# psoc6_03 register map
Vendor: Cypress Semiconductor; Series: PSoC6_03; File version: 1.0
CPU: CM4 r0p1, little endian, MPU, FPU, VTOR, 3 interrupt priority bits
Registers are 32-bit, read-write, reset 0x0 unless marked. A register's access mark holds for its fields unless they carry their own. Offsets are from the block's base; [hi:lo] are bit positions; {n}, {i} and the like mark numbered series; 'fields as' and 'values as' point back to an identical list; <NAME> marks a mode.

## CPUSS — CPU subsystem (CPUSS)
Base 0x40200000
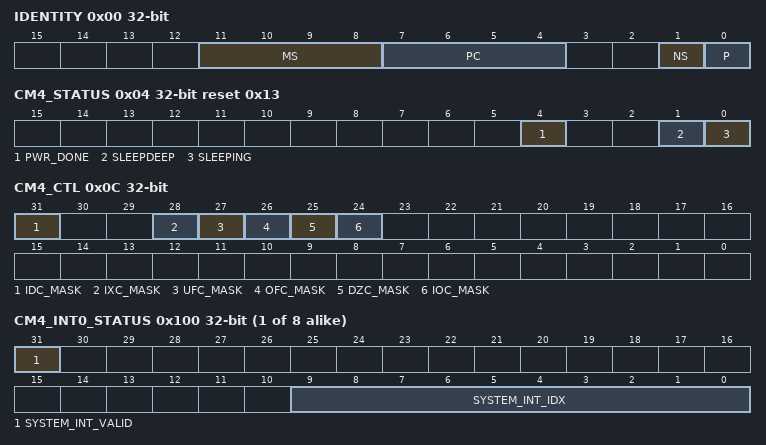
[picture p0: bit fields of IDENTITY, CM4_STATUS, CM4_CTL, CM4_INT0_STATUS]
0x00 IDENTITY ro reset not defined
  [11:8] MS — This field specifies the bus master identifier of the transfer that reads the register.
  [7:4] PC — This field specifies the protection context of the transfer that reads the register.
  [1] NS — This field specifies the security setting ('0': secure mode; '1': non-secure mode) of the transfer that reads the register.
  [0] P — This field specifies the privileged setting ('0': user mode; '1': privileged mode) of the transfer that reads the register.
0x04 CM4_STATUS ro reset 0x13
  [4] PWR_DONE — After a PWR_MODE change this flag indicates if the new power mode has taken effect or not. Note: this flag can also change as a result of a change in debug power up req
  [1] SLEEPDEEP — Specifies if the CPU is in Sleep or DeepSleep power mode. See SLEEPING field.
  [0] SLEEPING — Specifies if the CPU is in Active, Sleep or DeepSleep power mode: - Active power mode: SLEEPING is '0'. - Sleep power mode: SLEEPING is '1' and SLEEPDEEP is '0'. - DeepSleep power mode: SLEEPING is '1' and SLEEPDEEP is '1'.
0x08 CM4_CLOCK_CTL — CM4 clock control
  [15:8] FAST_INT_DIV — Specifies the fast clock divider (from the high frequency clock 'clk_hf' to the peripheral clock 'clk_fast'). Integer division by (1+FAST_INT_DIV). Allows for integer divisions in the range [1, 256] (FAST_INT_DIV is in the range [0, 255]). Note that this field is retained. However, the counter that is used to implement the division is not and will be initialized by HW to '0' when transitioning from DeepSleep to Active power mode.
0x0C CM4_CTL — CM4 control
  [31] IDC_MASK — CPU FPU exception mask for the CPU's FPCSR.IDC 'input denormalized' exception condition: '0': The CPU's exception condition does NOT activate the CPU's floating point interrupt. '1': the CPU's exception condition activates the CPU's floating point interrupt. Note: if the CPU FPCSR.FZ field is set to '1', denormalized inputs are 'flushed to zero'. Dependent on the FPU algorithm, this may or may not occur frequently. To prevent frequent CPU FPU interrupts as a result of denormalized inputs, this field may be set to '0'.
  [28] IXC_MASK — CPU FPU exception mask for the CPU's FPCSR.IXC 'inexact' exception condition: '0': The CPU's exception condition does NOT activate the CPU's floating point interrupt. '1': the CPU's exception condition activates the CPU's floating point interrupt. Note: the 'inexact' condition is set as a result of rounding. Rounding may occur frequently and is typically not an error condition. To prevent frequent CPU FPU interrupts as a result of rounding, this field is typically set to '0'.
  [27] UFC_MASK — CPU FPU exception mask for the CPU's FPCSR.UFC 'underflow' exception condition: '0': The CPU's exception condition does NOT activate the CPU's floating point interrupt. '1': the CPU's exception condition activates the CPU's floating point interrupt.
  [26] OFC_MASK — CPU FPU exception mask for the CPU's FPCSR.OFC 'overflow' exception condition: '0': The CPU's exception condition does NOT activate the CPU's floating point interrupt. '1': the CPU's exception condition activates the CPU's floating point interrupt.
  [25] DZC_MASK — CPU FPU exception mask for the CPU's FPCSR.DZC 'divide by zero' exception condition: '0': The CPU's exception condition does NOT activate the CPU's floating point interrupt. '1': the CPU's exception condition activates the CPU's floating point interrupt.
  [24] IOC_MASK — CPU floating point unit (FPU) exception mask for the CPU's FPCSR.IOC 'invalid operation' exception condition: '0': The CPU's exception condition does NOT activate the CPU's floating point interrupt. '1': the CPU's exception condition activates the CPU's floating point interrupt. Note: the ARM architecture does NOT support FPU exceptions; i.e. there is no precise FPU exception handler. Instead, FPU conditions are captured in the CPU's FPCSR register and the conditions are provided as CPU interface signals. The interface signals are 'masked' with the fields a provide by this register (CM7_0_CTL). The 'masked' signals are reduced/OR-ed into a single CPU floating point interrupt signal. The associated CPU interrupt handler allows for imprecise handling of FPU exception conditions. Note: the CPU's FPCSR exception conditions are 'sticky'. Typically, the CPU FPU interrupt handler will clear the exception condition(s) to '0'. Note: by default, the FPU exception masks are '0'. Therefore, FPU exception conditions will NOT activate the CPU's floating point interrupt.
{0x100+4i} CM4_INT{i}_STATUS ro (reset mask 0x80000000) (i=0..7) — CM4 interrupt {i} status
  [31] SYSTEM_INT_VALID — See description of CM0_INT0_STATUS.
  [9:0] SYSTEM_INT_IDX — Lowest CM4 activated system interrupt index for CPU interrupt {i}. See description of CM0_INT0_STATUS.
0x200 CM4_VECTOR_TABLE_BASE
  [31:10] ADDR22 — Address of CM4 vector table. This register is used for CM4 warm and cold boot purposes: the CM0+ CPU initializes the CM4_VECTOR_TABLE_BASE register and the CM4 boot code uses the register to initialize the CM4 internal VTOR register. Note: the CM4 vector table is at an address that is a 1024 B multiple.
{0x240+4i} CM4_NMI_CTL[{i}] (i=0..3) reset 0x3FF — CM4 NMI control
  [9:0] SYSTEM_INT_IDX — System interrupt select for CPU NMI. The reset value ('1023') ensures that the CPU NMI is NOT connected to any system interrupt after DeepSleep reset.
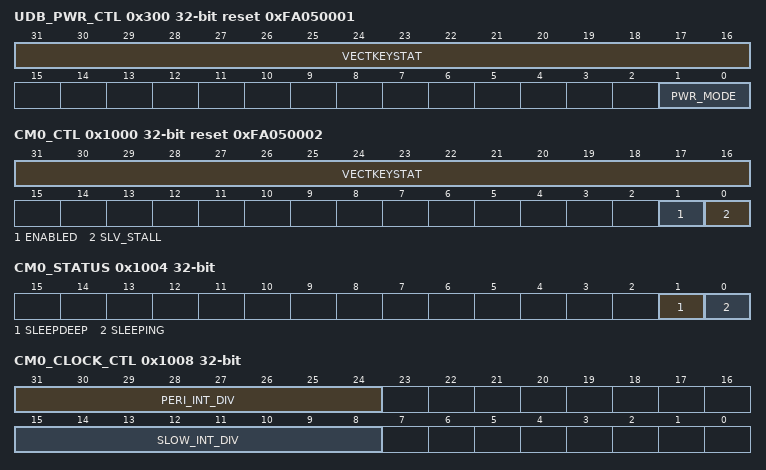
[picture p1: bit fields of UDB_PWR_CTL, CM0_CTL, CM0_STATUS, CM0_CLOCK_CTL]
0x300 UDB_PWR_CTL reset 0xFA050001 — UDB power control
  [31:16] VECTKEYSTAT ro — Register key (to prevent accidental writes). - Should be written with a 0x05fa key value for the write to take effect. - Always reads as 0xfa05.
  [1:0] PWR_MODE — Set Power mode for UDBs
    0=OFF (See CM4_PWR_CTL); 1=RESET (See CM4_PWR_CTL); 2=RETAINED (See CM4_PWR_CTL); 3=ENABLED (See CM4_PWR_CTL)
0x304 UDB_PWR_DELAY_CTL reset 0x12C — UDB power control
  [9:0] UP — Number clock cycles delay needed after power domain power up
0x1000 CM0_CTL reset 0xFA050002 — CM0+ control
  [31:16] VECTKEYSTAT ro — Register key (to prevent accidental writes). - Should be written with a 0x05fa key value for the write to take effect. - Always reads as 0xfa05. Note: Although the SW attribute for this field says ''R', SW need to write the key 0x05fa in this field for this register write to happen. This is a built in protection provided to prevent accidental writes from SW.
  [1] ENABLED — Processor enable: '0': Disabled. Processor clock is turned off and reset is activated. After SW clears this field to '0', HW automatically sets this field to '1'. This effectively results in a CM0+ reset, followed by a CM0+ warm boot. '1': Enabled. Note: The intent is that this bit is modified only through an external probe or by the CM4 while the CM0+ is in Sleep or DeepSleep power mode. If this field is cleared to '0' by the CM0+ itself, it should be done under controlled conditions (such that undesirable side effects can be prevented). Note: The CM0+ CPU has a AIRCR.SYSRESETREQ register field that allows the CM0+ to reset the complete device (ENABLED only disables/enables the CM0+), resulting in a warm boot. This CPU register field has similar 'built-in protection' as this CM0_CTL register to prevent accidental system writes (the upper 16-bits of the register need to be written with a 0x05fa key value; see CPU user manual for more details).
  [0] SLV_STALL — Processor debug access control: '0': Access. '1': Stall access. This field is used to stall/delay debug accesses. This is useful to protect execution of code that needs to be protected from debug accesses.
0x1004 CM0_STATUS ro
  [1] SLEEPDEEP — Specifies if the CPU is in Sleep or DeepSleep power mode. See SLEEPING field.
  [0] SLEEPING — Specifies if the CPU is in Active, Sleep or DeepSleep power mode: - Active power mode: SLEEPING is '0'. - Sleep power mode: SLEEPING is '1' and SLEEPDEEP is '0'. - DeepSleep power mode: SLEEPING is '1' and SLEEPDEEP is '1'.
0x1008 CM0_CLOCK_CTL — CM0+ clock control
  [31:24] PERI_INT_DIV — Specifies the peripheral clock divider (from the high frequency clock 'clk_hf' to the peripheral clock 'clk_peri'). Integer division by (1+PERI_INT_DIV). Allows for integer divisions in the range [1, 256] (PERI_INT_DIV is in the range [0, 255]). Note that this field is retained. However, the counter that is used to implement the division is not and will be initialized by HW to '0' when transitioning from DeepSleep to Active power mode. Note that Fperi <= Fperi_max. Fperi_max is likely to be smaller than Fhf_max. In other words, if Fhf = Fhf_max, PERI_INT_DIV should not be set to '0'.
  [15:8] SLOW_INT_DIV — Specifies the slow clock divider (from the peripheral clock 'clk_peri' to the slow clock 'clk_slow'). Integer division by (1+SLOW_INT_DIV). Allows for integer divisions in the range [1, 256] (SLOW_INT_DIV is in the range [0, 255]). Note that this field is retained. However, the counter that is used to implement the division is not and will be initialized by HW to '0' when transitioning from DeepSleep to Active power mode.
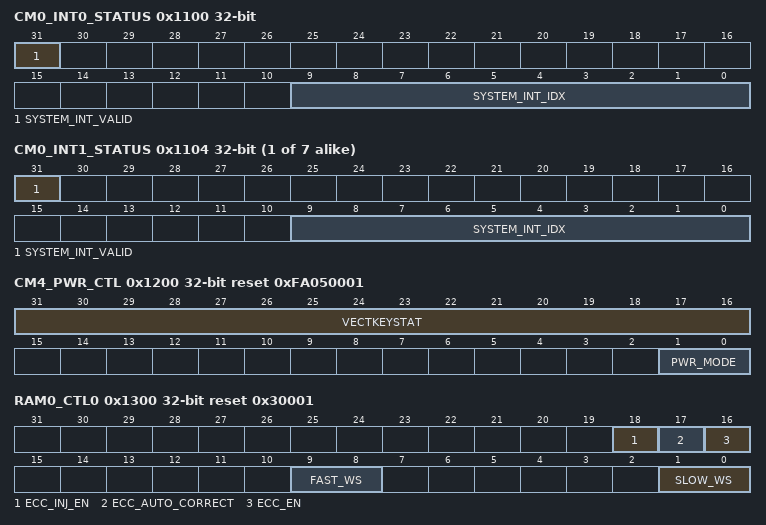
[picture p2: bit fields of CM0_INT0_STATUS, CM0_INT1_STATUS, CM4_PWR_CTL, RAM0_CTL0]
0x1100 CM0_INT0_STATUS ro (reset mask 0x80000000) — CM0+ interrupt 0 status
  [31] SYSTEM_INT_VALID — Valid indication for SYSTEM_INT_IDX. When '0', no system interrupt for CPU interrupt 0 is valid/activated.
  [9:0] SYSTEM_INT_IDX — Lowest CM0+ activated system interrupt index for CPU interrupt 0. Multiple system interrupts can be mapped on the same CPU interrupt. The selected system interrupt is the system interrupt with the lowest system interrupt index that has an activated interrupt request at the time of the fetch (system_interrupts[SYSTEM_INT_IDX] is '1'). The CPU interrupt handler SW can read SYSTEM_INT_IDX to determine the system interrupt that activated the handler.
{0x1100+4i} CM0_INT{i}_STATUS ro (reset mask 0x80000000) (i=1..7) — CM0+ interrupt {i} status
  [31] SYSTEM_INT_VALID — See description of CM0_INT0_STATUS.
  [9:0] SYSTEM_INT_IDX — Lowest CM0+ activated system interrupt index for CPU interrupt {i}. See description of CM0_INT0_STATUS.
0x1120 CM0_VECTOR_TABLE_BASE
  [31:8] ADDR24 — Address of CM0+ vector table. This register is used for CM0+ warm boot purposes: the CM0+ warm boot code uses the register to initialize the CM0+ internal VTOR register. Note: the CM0+ vector table is at an address that is a 256 B multiple.
{0x1140+4i} CM0_NMI_CTL[{i}] (i=0..3) reset 0x3FF — CM0+ NMI control
  fields as CM4_NMI_CTL[0]
0x1200 CM4_PWR_CTL reset 0xFA050001 — CM4 power control
  [31:16] VECTKEYSTAT ro — Register key (to prevent accidental writes). - Should be written with a 0x05fa key value for the write to take effect. - Always reads as 0xfa05. Note: Although the SW attribute for this field says ''R', SW need to write the key 0x05fa in this field for this register write to happen. This is a built in protection provided to prevent accidental writes from SW.
  [1:0] PWR_MODE — Power mode.
    0=OFF (Switch CM4 off Power off, clock off, isolate, reset and no retain.); 1=RESET (Reset CM4 Clock off, no isolated, no retain and reset. Note: The CM4 CPU has a AIRCR.SYSRESETREQ register field that allows the CM4 to reset the complete device (RESET only resets the CM4), resulting in a warm boot.); 2=RETAINED (Put CM4 in Retained mode This can only become effective if CM4 is in SleepDeep mode. Check PWR_DONE flag to see if CM4 RETAINED state has been reached. Power off, clock off, isolate, no reset and retain.); 3=ENABLED (Switch CM4 on. Power on, clock on, no isolate, no reset and no retain.)
0x1204 CM4_PWR_DELAY_CTL reset 0x12C — CM4 power control
  fields as UDB_PWR_DELAY_CTL
0x1300 RAM0_CTL0 reset 0x30001 — RAM 0 control
  [18] ECC_INJ_EN — Enable error injection for system SRAM 0. When '1', the parity (ECC_CTL.PARITY) is used when a full 32-bit write is done to the ECC_CTL.WORD_ADDR word address of system SRAM 0.
  [17] ECC_AUTO_CORRECT — HW ECC autocorrect functionality: '0': Disabled. '1': Enabled. HW automatically writes back SRAM with corrected data when a recoverable ECC error is detected.
  [16] ECC_EN — Enable ECC checking: '0': Disabled. '1': Enabled.
  [9:8] FAST_WS — Memory wait states for the fast clock domain ('clk_fast'). The number of wait states is expressed in 'clk_hf' clock domain cycles.
  [1:0] SLOW_WS — Memory wait states for the slow clock domain ('clk_slow'). The number of wait states is expressed in 'clk_hf' clock domain cycles.
0x1304 RAM0_STATUS ro reset 0x1
  [0] WB_EMPTY — Write buffer empty. This information is used when entering DeepSleep power mode: WB_EMPTY must be '1' before a transition to system DeepSleep power mode. '0': Write buffer NOT empty. '1': Write buffer empty. Note: the SRAM controller write buffer is only used when ECC checking is enabled. (RAMi_CTL.ECC_EN is '1').
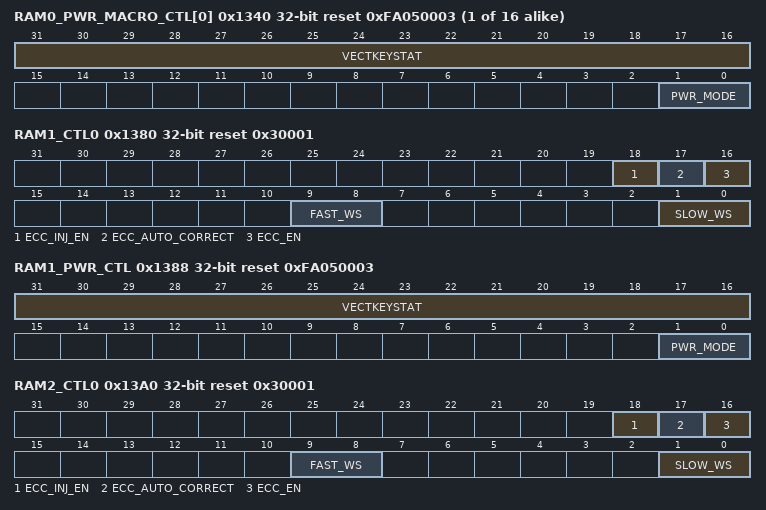
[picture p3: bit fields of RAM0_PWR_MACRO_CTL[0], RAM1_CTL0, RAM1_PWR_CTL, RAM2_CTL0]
{0x1340+4i} RAM0_PWR_MACRO_CTL[{i}] (i=0..15) reset 0xFA050003 — RAM 0 power control
  [31:16] VECTKEYSTAT ro — Register key (to prevent accidental writes). - Should be written with a 0x05fa key value for the write to take effect. - Always reads as 0xfa05. Note: Although the SW attribute for this field says ''R', SW need to write the key 0x05fa in this field for this register write to happen. This is a built in protection provided to prevent accidental writes from SW.
  [1:0] PWR_MODE — SRAM Power mode.
    0=OFF (Turn OFF the SRAM. This will trun OFF both array and periphery power of the SRAM and SRAM memory contents are lost.); 1=RSVD (undefined); 2=RETAINED (Keep SRAM in Retained mode. This will turn OFF the SRAM periphery power, but array power is ON to retain memory contents. The SRAM contents will be retained in DeepSleep system power mode.); 3=ENABLED (Enable SRAM for regular operation. The SRAM contents will be retained in DeepSleep system power mode.)
0x1380 RAM1_CTL0 reset 0x30001 — RAM 1 control
  [18] ECC_INJ_EN — See RAM0_CTL.
  [17] ECC_AUTO_CORRECT — See RAM0_CTL.
  [16] ECC_EN — See RAM0_CTL.
  [9:8] FAST_WS — See RAM0_CTL.
  [1:0] SLOW_WS — See RAM0_CTL.
0x1384 RAM1_STATUS ro reset 0x1
  [0] WB_EMPTY — See RAM0_STATUS.
0x1388 RAM1_PWR_CTL reset 0xFA050003 — RAM 1 power control
  [31:16] VECTKEYSTAT ro — See RAM0_PWR_MACRO_CTL.
  [1:0] PWR_MODE — Power mode.
    0=OFF (See RAM0_PWR_MACRO_CTL.); 1=RSVD (undefined); 2=RETAINED (See RAM0_PWR_MACRO_CTL.); 3=ENABLED (See RAM0_PWR_MACRO_CTL.)
0x13A0 RAM2_CTL0 reset 0x30001 — RAM 2 control
  fields as RAM1_CTL0
0x13A4 RAM2_STATUS ro reset 0x1
  [0] WB_EMPTY — See RAM0_STATUS.
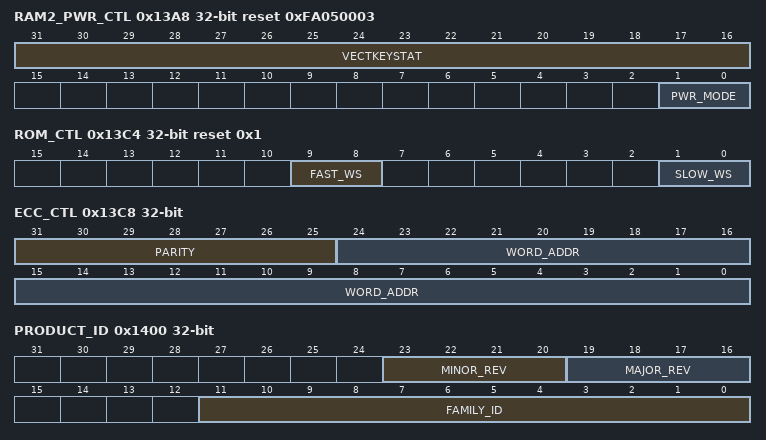
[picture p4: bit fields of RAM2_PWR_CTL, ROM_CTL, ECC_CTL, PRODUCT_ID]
0x13A8 RAM2_PWR_CTL reset 0xFA050003 — RAM 2 power control
  fields as RAM1_PWR_CTL
0x13C0 RAM_PWR_DELAY_CTL reset 0x96 — Power up delay used for all SRAM power domains
  [9:0] UP — Number clock cycles (clk_slow) delay needed after power domain power up
0x13C4 ROM_CTL reset 0x1 — ROM control
  [9:8] FAST_WS — Memory wait states for the fast clock domain ('clk_fast'). The number of wait states is expressed in 'clk_hf' clock domain cycles. ROM_CTL.FAST_WS = '0' when clk_hf <= clk_hf_max.
  [1:0] SLOW_WS — Memory wait states for the slow clock domain ('clk_slow'). The number of wait states is expressed in 'clk_hf' clock domain cycles. Timing paths to and from the memory have a (fixed) minimum duration that always needs to be considered/met. The 'clk_hf' clock domain frequency determines this field's value such that the timing paths minimum duration is met. ROM_CTL.SLOW_WS = '0' when clk_hf <=100 MHz. ROM_CTL.SLOW_WS = '1' when 100MHz < clk_hf <=clk_hf_max. Note: clk_hf_max depends on the target device. Refer datasheet.
0x13C8 ECC_CTL — ECC control
  [31:25] PARITY — ECC parity to use for ECC error injection at address WORD_ADDR.
  [24:0] WORD_ADDR — Specifies the word address where an error will be injected. - On a write transfer to this SRAM address and when the corresponding RAM0/RAM1/RAM2_CTL0.ECC_INJ_EN bit is '1', the parity (PARITY) is injected. This field needs to be written with the offset address within the memory, divided by 4. For example, if the RAM1 start address is 0x08010000, and an error is to be injected to address 0x08010040, then this field needs to configured to 0x000010.
0x1400 PRODUCT_ID ro (reset mask 0xFFF) — Product identifier and version (same as CoreSight RomTables)
  [23:20] MINOR_REV — Minor Revision, starts with 1, increments with metal layer only tape-out (implemented with metal ECO-able tie-off)
  [19:16] MAJOR_REV — Major Revision, starts with 1, increments with all layer tape-out (implemented with metal ECO-able tie-off)
  [11:0] FAMILY_ID — Family ID. Common ID for a product family.
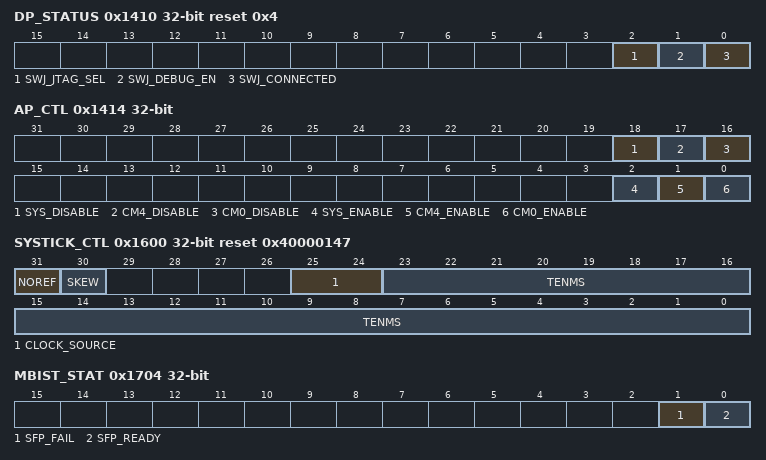
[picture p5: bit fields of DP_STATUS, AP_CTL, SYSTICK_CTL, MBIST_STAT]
0x1410 DP_STATUS ro reset 0x4 — Debug port status
  [2] SWJ_JTAG_SEL — Specifies if the JTAG or SWD interface is selected. This signal is valid when DP_CTL.PTM_SEL is '0' (SWJ mode selected) and SWJ_CONNECTED is '1' (SWJ is connected). '0': SWD selected. '1': JTAG selected.
  [1] SWJ_DEBUG_EN — Specifies if SWJ debug is enabled, i.e. CDBGPWRUPACK is '1' and thus debug clocks are on: '0': Disabled. '1': Enabled.
  [0] SWJ_CONNECTED — Specifies if the SWJ debug port is connected; i.e. debug host interface is active: '0': Not connected/not active. '1': Connected/active.
0x1414 AP_CTL — Access port control
  [18] SYS_DISABLE — Disables the system AP interface: '0': Enabled. '1': Disabled. Typically, this field is set by the Cypress boot code with information from eFUSE. The access port is only enabled when SYS_DISABLE is '0' and SYS_ENABLE is '1'.
  [17] CM4_DISABLE — Disables the CM4 AP interface: '0': Enabled. '1': Disabled. Typically, this field is set by the Cypress boot code with information from eFUSE. The access port is only enabled when CM4_DISABLE is '0' and CM4_ENABLE is '1'.
  [16] CM0_DISABLE — Disables the CM0 AP interface: '0': Enabled. '1': Disabled. Typically, this field is set by the Cypress boot code with information from eFUSE. The access port is only enabled when CM0_DISABLE is '0' and CM0_ENABLE is '1'.
  [2] SYS_ENABLE — Enables the system AP interface: '0': Disabled. '1': Enabled.
  [1] CM4_ENABLE — Enables the CM4 AP interface: '0': Disabled. '1': Enabled.
  [0] CM0_ENABLE — Enables the CM0 AP interface: '0': Disabled. '1': Enabled.
0x1500 BUFF_CTL reset 0x1 — Buffer control
  [0] WRITE_BUFF — Specifies if write transfer can be buffered in the bus infrastructure bridges: '0': Write transfers are not buffered, independent of the transfer's bufferable attribute. '1': Write transfers can be buffered, if the transfer's bufferable attribute indicates that the transfer is a bufferable/posted write.
0x1600 SYSTICK_CTL reset 0x40000147 — SysTick timer control
  [31] NOREF — Specifies if an external clock source is provided: '0': An external clock source is provided. '1': An external clock source is NOT provided and only the CPU internal clock can be used as SysTick timer clock source.
  [30] SKEW — Specifies the precision of the clock source and if the TENMS field represents exactly 10 ms (clock source frequency is a multiple of 100 Hz). This affects the suitability of the SysTick timer as a SW real-time clock: '0': Precise. '1': Imprecise.
  [25:24] CLOCK_SOURCE — Specifies an external clock source: '0': The low frequency clock 'clk_lf' is selected. The precision of this clock depends on whether the low frequency clock source is a SRSS internal RC oscillator (imprecise) or a device external crystal oscillator (precise). '1': The internal main oscillator (IMO) clock 'clk_imo' is selected. The MXS40 platform uses a fixed frequency IMO clock. o '2': The external crystal oscillator (ECO) clock 'clk_eco' is selected. '3': The SRSS 'clk_timer' is selected ('clk_timer' is a divided/gated version of 'clk_hf' or 'clk_imo'). Note: If NOREF is '1', the CLOCK_SOURCE value is NOT used. Note: It is SW's responsibility to provide the correct NOREF, SKEW and TENMS field values for the selected clock source.
  [23:0] TENMS — Specifies the number of clock source cycles (minus 1) that make up 10 ms. E.g., for a 32,768 Hz reference clock, TENMS is 328 - 1 = 327.
0x1704 MBIST_STAT ro — Memory BIST status
  [1] SFP_FAIL — Report status of the BIST run, only valid if SFP_READY=1
  [0] SFP_READY — Flag indicating the BIST run is done. Note that after starting a BIST run this flag must be set before a new run can be started. For the first BIST run this will be 0.
0x1800 CAL_SUP_SET — Calibration support set and read
  [31:0] DATA — Read without side effect, write 1 to set
0x1804 CAL_SUP_CLR — Calibration support clear and reset
  [31:0] DATA — Read side effect: when read all bits are cleared, write 1 to clear a specific bit Note: no exception for the debug host, it also causes the read side effect
0x2000 CM0_PC_CTL — CM0+ protection context control
  [3:0] VALID — Valid fields for the protection context handler CM0_PCi_HANDLER registers: Bit 0: Valid field for CM0_PC0_HANDLER. Bit 1: Valid field for CM0_PC1_HANDLER. Bit 2: Valid field for CM0_PC2_HANDLER. Bit 3: Valid field for CM0_PC3_HANDLER.
0x2040 CM0_PC0_HANDLER — CM0+ protection context 0 handler
  [31:0] ADDR — Address of the protection context 0 handler. This field is used to detect entry to Cypress 'trusted' code through an exception/interrupt.
{0x2040+4i} CM0_PC{i}_HANDLER (i=1..3) — CM0+ protection context {i} handler
  [31:0] ADDR — Address of the protection context {i} handler.
0x20C4 PROTECTION — Protection status
  [2:0] STATE — Protection state: '0': UNKNOWN. '1': VIRGIN. '2': NORMAL. '3': SECURE. '4': DEAD. The following state transitions are allowed (and enforced by HW): - UNKNOWN => VIRGIN/NORMAL/SECURE/DEAD - NORMAL => DEAD - SECURE => DEAD An attempt to make a NOT allowed state transition will NOT affect this register field.
0x2100 TRIM_ROM_CTL — ROM trim control
  [31:0] TRIM
0x2104 TRIM_RAM_CTL — RAM trim control
  [31:0] TRIM
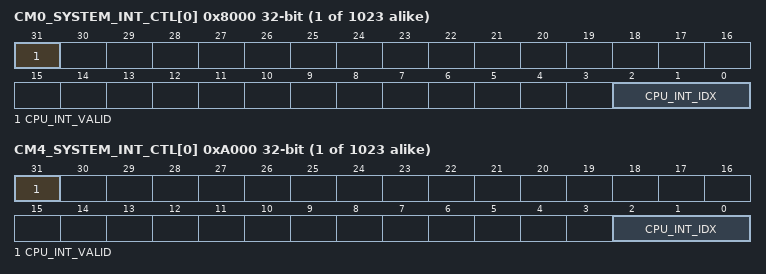
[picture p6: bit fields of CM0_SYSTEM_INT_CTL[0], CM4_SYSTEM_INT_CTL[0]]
{0x8000+4i} CM0_SYSTEM_INT_CTL[{i}] (i=0..1022) (reset mask 0x80000000) — CM0+ system interrupt control
  [31] CPU_INT_VALID — Interrupt enable: '0': Disabled. The system interrupt will NOT be mapped to any CPU interrupt. '1': Enabled. The system interrupt is mapped on CPU interrupt CPU_INT_IDX. Note: the CPUs have dedicated XXX_SYSTEM_INT_CTL registers. In other words, the CPUs can use different CPU interrupts for the same system interrupt. However, typically only one of the CPUs will have the ENABLED field of a specific system interrupt set to '1'.
  [2:0] CPU_INT_IDX — CPU interrupt index (legal range [0, 7]). This field specifies to which CPU interrupt the system interrupt is mapped. E.g., if CPU_INT_IDX is '6', the system interrupt is mapped to CPU interrupt '6'. Note: it is possible to map multiple system interrupts to the same CPU interrupt. It is advised to assign different priorities to the CPU interrupts and to assign system interrupts to CPU interrupts accordingly.
{0xA000+4i} CM4_SYSTEM_INT_CTL[{i}] (i=0..1022) (reset mask 0x80000000) — CM4 system interrupt control
  [31] CPU_INT_VALID, [2:0] CPU_INT_IDX

## Notices in the file
Copyright 2016-2020 Cypress Semiconductor Corporation
SPDX-License-Identifier: Apache-2.0
Licensed under the Apache License, Version 2.0 (the "License");
you may not use this file except in compliance with the License.
You may obtain a copy of the License at
http://www.apache.org/licenses/LICENSE-2.0
Unless required by applicable law or agreed to in writing, software
distributed under the License is distributed on an "AS IS" BASIS,
WITHOUT WARRANTIES OR CONDITIONS OF ANY KIND, either express or implied.
See the License for the specific language governing permissions and
limitations under the License.
